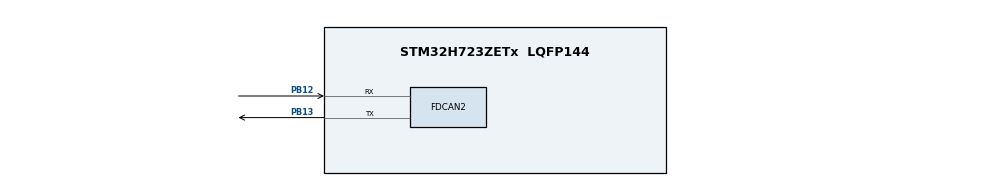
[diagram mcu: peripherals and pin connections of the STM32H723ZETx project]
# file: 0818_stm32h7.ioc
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CORTEX_M7.CPU_DCache=Enabled
CORTEX_M7.CPU_ICache=Enabled
CORTEX_M7.DisableExec_Spec=MPU_INSTRUCTION_ACCESS_ENABLE
CORTEX_M7.IsCacheable_Spec=MPU_ACCESS_NOT_CACHEABLE
CORTEX_M7.IsShareable_Spec=MPU_ACCESS_NOT_SHAREABLE
CORTEX_M7.default_mode_Activation=1
FDCAN2.CalculateBaudRateNominal=1000000
FDCAN2.CalculateTimeBitNominal=1000
FDCAN2.CalculateTimeQuantumNominal=25.0
FDCAN2.DataTimeSeg1=29
FDCAN2.DataTimeSeg2=10
FDCAN2.ExtFiltersNbr=16
FDCAN2.MessageRAMOffset=850
FDCAN2.Mode=FDCAN_MODE_NORMAL
FDCAN2.NominalPrescaler=1
FDCAN2.NominalSyncJumpWidth=5
FDCAN2.NominalTimeSeg1=29
FDCAN2.NominalTimeSeg2=10
FDCAN2.RxFifo0ElmtsNbr=12
FDCAN2.RxFifo1ElmtsNbr=12
FDCAN2.StdFiltersNbr=16
FDCAN2.TxBuffersNbr=16
FDCAN2.TxFifoQueueElmtsNbr=16
FREERTOS.Tasks01=defaultTask,24,128,StartDefaultTask,Default,NULL,Dynamic,NULL,NULL
Mcu.Family=STM32H7
Mcu.Name=STM32H723ZETx
Mcu.Package=LQFP144
NVIC.FDCAN2_IT0_IRQn=true\:5\:0\:false\:false\:true\:true\:true\:true\:true
NVIC.FDCAN2_IT1_IRQn=true\:5\:0\:false\:false\:true\:true\:true\:true\:true
NVIC.PriorityGroup=NVIC_PRIORITYGROUP_4
NVIC.TIM1_UP_IRQn=true\:15\:0\:false\:false\:true\:false\:false\:true\:true
NVIC.TIM2_IRQn=true\:5\:0\:false\:false\:true\:true\:true\:true\:true
NVIC.TimeBase=TIM1_UP_IRQn
NVIC.TimeBaseIP=TIM1
PB12.GPIO_PuPd=GPIO_PULLUP
PB12.Mode=FDCAN_Activate
PB12.Signal=FDCAN2_RX
PB13.Mode=FDCAN_Activate
PB13.Signal=FDCAN2_TX
PH0-OSC_IN.Mode=HSE-External-Oscillator
PH0-OSC_IN.Signal=RCC_OSC_IN
PH1-OSC_OUT.Mode=HSE-External-Oscillator
PH1-OSC_OUT.Signal=RCC_OSC_OUT
ProjectManager.HeapSize=0x200
ProjectManager.StackSize=0x400
ProjectManager.TargetToolchain=MDK-ARM V5.32
RCC.ADCFreq_Value=100000000
RCC.APB1Freq_Value=137500000
RCC.APB2Freq_Value=137500000
RCC.APB3Freq_Value=137500000
RCC.APB4Freq_Value=137500000
RCC.CortexFreq_Value=550000000
RCC.D1PPRE=RCC_APB3_DIV2
RCC.D2PPRE1=RCC_APB1_DIV2
RCC.D2PPRE2=RCC_APB2_DIV2
RCC.D3PPRE=RCC_APB4_DIV2
RCC.DIVM1=2
RCC.DIVM2=2
RCC.DIVN1=44
RCC.DIVN2=16
RCC.DIVP1=1
RCC.DIVQ1=4
RCC.DIVQ2=5
RCC.FDCANCLockSelection=RCC_FDCANCLKSOURCE_PLL2
RCC.HCLKFreq_Value=275000000
RCC.HPRE=RCC_HCLK_DIV2
RCC.PLLFRACN=0
RCC.PLLSourceVirtual=RCC_PLLSOURCE_HSE
RCC.SYSCLKFreq_VALUE=550000000
RCC.SYSCLKSource=RCC_SYSCLKSOURCE_PLLCLK
RCC.USBFreq_Value=137500000
TIM2.Period=1000-1
TIM2.Prescaler=275-1
VP_FREERTOS_VS_CMSIS_V2.Mode=CMSIS_V2
VP_MEMORYMAP_VS_MEMORYMAP.Mode=CurAppReg
VP_SYS_VS_tim1.Mode=TIM1
VP_TIM2_VS_ClockSourceINT.Mode=Internal
board=custom

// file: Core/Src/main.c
/* USER CODE BEGIN Header */
/**
  ******************************************************************************
  * @file           : main.c
  * @brief          : Main program body
  ******************************************************************************
  * @attention
  *
  * Copyright (c) 2026 STMicroelectronics.
  * All rights reserved.
  *
  * This software is licensed under terms that can be found in the LICENSE file
  * in the root directory of this software component.
  * If no LICENSE file comes with this software, it is provided AS-IS.
  *
  ******************************************************************************
  */
/* USER CODE END Header */
#include "main.h"
#include "FreeRTOS.h"
#include "cmsis_os2.h"
#include "fdcan.h"
#include "tim.h"
#include "gpio.h"

/* USER CODE BEGIN Includes */
#include "DJmotor.h"
#include "Tim_IRQ_Handler.h"
#include "fdCan_IRQ_Handler.h"
/* USER CODE END Includes */

void SystemClock_Config(void);
static void MPU_Config(void);
void MX_FREERTOS_Init(void);

int main(void)
{

  /* USER CODE BEGIN 1 */
	const uint8_t data[]={0};
  /* USER CODE END 1 */

  /* MPU Configuration--------------------------------------------------------*/
  MPU_Config();

  /* Enable the CPU Cache */

  /* Enable I-Cache---------------------------------------------------------*/
  SCB_EnableICache();

  /* Enable D-Cache---------------------------------------------------------*/
  SCB_EnableDCache();

  /* MCU Configuration--------------------------------------------------------*/

  /* Reset of all peripherals, Initializes the Flash interface and the Systick. */
  HAL_Init();

  /* USER CODE BEGIN Init */
  ZdriveInit();
  /* USER CODE END Init */

  /* Configure the system clock */
  SystemClock_Config();

  /* Initialize all configured peripherals */
  MX_GPIO_Init();
  MX_FDCAN2_Init();
  MX_TIM2_Init();
  /* USER CODE BEGIN 2 */
  Tim2_Start();
  fdCan_Start();
	fdCAN_Send_Data(0,0x001,1,data);
  /* USER CODE END 2 */

  /* Init scheduler */
  osKernelInitialize();  /* Call init function for freertos objects (in cmsis_os2.c) */
  MX_FREERTOS_Init();

  /* Start scheduler */
  osKernelStart();

  /* We should never get here as control is now taken by the scheduler */

  /* Infinite loop */
  while (1)
  {

  }
}

void SystemClock_Config(void)
{
  RCC_OscInitTypeDef RCC_OscInitStruct = {0};
  RCC_ClkInitTypeDef RCC_ClkInitStruct = {0};

  /** Supply configuration update enable
  */
  HAL_PWREx_ConfigSupply(PWR_LDO_SUPPLY);

  /** Configure the main internal regulator output voltage
  */
  __HAL_PWR_VOLTAGESCALING_CONFIG(PWR_REGULATOR_VOLTAGE_SCALE0);

  while(!__HAL_PWR_GET_FLAG(PWR_FLAG_VOSRDY)) {}

  /** Initializes the RCC Oscillators according to the specified parameters
  * in the RCC_OscInitTypeDef structure.
  */
  RCC_OscInitStruct.OscillatorType = RCC_OSCILLATORTYPE_HSE;
  RCC_OscInitStruct.HSEState = RCC_HSE_ON;
  RCC_OscInitStruct.PLL.PLLState = RCC_PLL_ON;
  RCC_OscInitStruct.PLL.PLLSource = RCC_PLLSOURCE_HSE;
  RCC_OscInitStruct.PLL.PLLM = 2;
  RCC_OscInitStruct.PLL.PLLN = 44;
  RCC_OscInitStruct.PLL.PLLP = 1;
  RCC_OscInitStruct.PLL.PLLQ = 4;
  RCC_OscInitStruct.PLL.PLLR = 2;
  RCC_OscInitStruct.PLL.PLLRGE = RCC_PLL1VCIRANGE_3;
  RCC_OscInitStruct.PLL.PLLVCOSEL = RCC_PLL1VCOWIDE;
  RCC_OscInitStruct.PLL.PLLFRACN = 0;
  if (HAL_RCC_OscConfig(&RCC_OscInitStruct) != HAL_OK)
  {
    Error_Handler();
  }

  /** Initializes the CPU, AHB and APB buses clocks
  */
  RCC_ClkInitStruct.ClockType = RCC_CLOCKTYPE_HCLK|RCC_CLOCKTYPE_SYSCLK
                              |RCC_CLOCKTYPE_PCLK1|RCC_CLOCKTYPE_PCLK2
                              |RCC_CLOCKTYPE_D3PCLK1|RCC_CLOCKTYPE_D1PCLK1;
  RCC_ClkInitStruct.SYSCLKSource = RCC_SYSCLKSOURCE_PLLCLK;
  RCC_ClkInitStruct.SYSCLKDivider = RCC_SYSCLK_DIV1;
  RCC_ClkInitStruct.AHBCLKDivider = RCC_HCLK_DIV2;
  RCC_ClkInitStruct.APB3CLKDivider = RCC_APB3_DIV2;
  RCC_ClkInitStruct.APB1CLKDivider = RCC_APB1_DIV2;
  RCC_ClkInitStruct.APB2CLKDivider = RCC_APB2_DIV2;
  RCC_ClkInitStruct.APB4CLKDivider = RCC_APB4_DIV2;

  if (HAL_RCC_ClockConfig(&RCC_ClkInitStruct, FLASH_LATENCY_3) != HAL_OK)
  {
    Error_Handler();
  }
}

 /* MPU Configuration */

void MPU_Config(void)
{
  MPU_Region_InitTypeDef MPU_InitStruct = {0};

  /* Disables the MPU */
  HAL_MPU_Disable();

  /** Initializes and configures the Region and the memory to be protected
  */
  MPU_InitStruct.Enable = MPU_REGION_ENABLE;
  MPU_InitStruct.Number = MPU_REGION_NUMBER0;
  MPU_InitStruct.BaseAddress = 0x0;
  MPU_InitStruct.Size = MPU_REGION_SIZE_4GB;
  MPU_InitStruct.SubRegionDisable = 0x87;
  MPU_InitStruct.TypeExtField = MPU_TEX_LEVEL0;
  MPU_InitStruct.AccessPermission = MPU_REGION_NO_ACCESS;
  MPU_InitStruct.DisableExec = MPU_INSTRUCTION_ACCESS_ENABLE;
  MPU_InitStruct.IsShareable = MPU_ACCESS_NOT_SHAREABLE;
  MPU_InitStruct.IsCacheable = MPU_ACCESS_NOT_CACHEABLE;
  MPU_InitStruct.IsBufferable = MPU_ACCESS_NOT_BUFFERABLE;

  HAL_MPU_ConfigRegion(&MPU_InitStruct);
  /* Enables the MPU */
  HAL_MPU_Enable(MPU_PRIVILEGED_DEFAULT);

}

void HAL_TIM_PeriodElapsedCallback(TIM_HandleTypeDef *htim)
{
  if (htim->Instance == TIM1)
  {
    HAL_IncTick();
  }
  /* USER CODE BEGIN Callback 1 */

  TIM_PeriodElapsedCallback(htim);

  /* USER CODE END Callback 1 */
}

void Error_Handler(void)
{
  __disable_irq();
  while (1)
  {
  }
}

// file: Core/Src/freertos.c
/* USER CODE BEGIN Header */
/**
  ******************************************************************************
  * File Name          : freertos.c
  * Description        : Code for freertos applications
  ******************************************************************************
  * @attention
  *
  * Copyright (c) 2026 STMicroelectronics.
  * All rights reserved.
  *
  * This software is licensed under terms that can be found in the LICENSE file
  * in the root directory of this software component.
  * If no LICENSE file comes with this software, it is provided AS-IS.
  *
  ******************************************************************************
  */
/* USER CODE END Header */

#include "FreeRTOS.h"
#include "task.h"
#include "main.h"
#include "FreeRTOS.h"
#include "cmsis_os2.h"

/* USER CODE BEGIN Includes */
#include "app_tasks.h"
/* USER CODE END Includes */

/* Definitions for defaultTask */
osThreadId_t defaultTaskHandle;
const osThreadAttr_t defaultTask_attributes = {
  .name = "defaultTask",
  .stack_size = 128 * 4,
  .priority = (osPriority_t) osPriorityNormal,
};

void StartDefaultTask(void *argument);

void MX_FREERTOS_Init(void); /* (MISRA C 2004 rule 8.1) */

void MX_FREERTOS_Init(void) {

  /* Create the thread(s) */
  /* creation of defaultTask */
  defaultTaskHandle = osThreadNew(StartDefaultTask, NULL, &defaultTask_attributes);

  /* USER CODE BEGIN RTOS_THREADS */
  app_tasks_create();
  /* add threads, ... */
  /* USER CODE END RTOS_THREADS */

}

void StartDefaultTask(void *argument)
{
  for(;;)
  {
    osDelay(1);
  }
}
